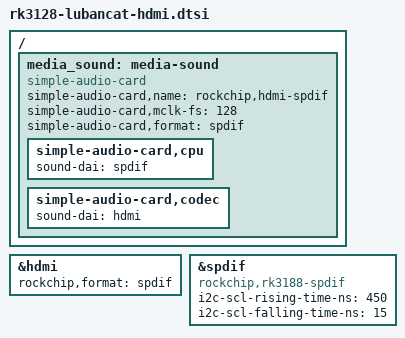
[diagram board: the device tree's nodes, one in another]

/ {
	media_sound: media-sound {
		status = "okay";
		compatible = "simple-audio-card";
		simple-audio-card,name = "rockchip,hdmi-spdif";
		simple-audio-card,mclk-fs = <128>;
		simple-audio-card,format = "spdif";
		simple-audio-card,cpu {
			sound-dai = <&spdif>;
		};
		simple-audio-card,codec {
			sound-dai = <&hdmi>;
		};
	};
};

&hdmi {
	rockchip,format = "spdif";
	#sound-dai-cells = <0>;
	status = "okay";
};

&spdif{
	compatible = "rockchip,rk3188-spdif";
	status = "okay";
	i2c-scl-rising-time-ns = <450>;
	i2c-scl-falling-time-ns = <15>;
	#sound-dai-cells = <0>;
};
